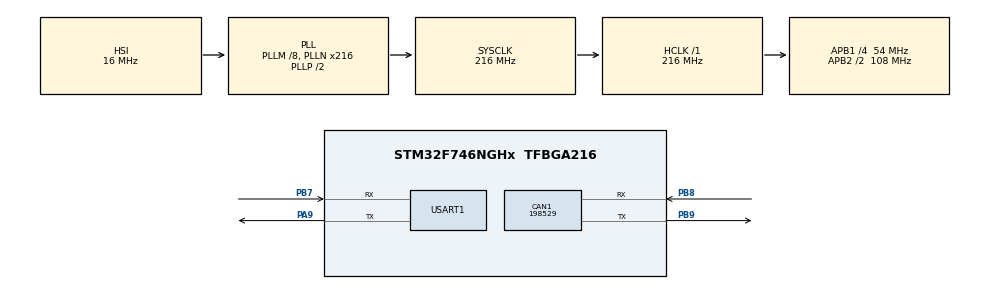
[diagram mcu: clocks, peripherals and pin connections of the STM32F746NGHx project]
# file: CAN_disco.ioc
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CAN1.BS1=CAN_BS1_8TQ
CAN1.BS2=CAN_BS2_8TQ
CAN1.CalculateBaudRate=198529
CAN1.CalculateTimeBit=5037
CAN1.CalculateTimeQuantum=296.2962962962963
CAN1.NART=ENABLE
CAN1.SJW=CAN_SJW_4TQ
Mcu.Family=STM32F7
Mcu.Name=STM32F746NGHx
Mcu.Package=TFBGA216
NVIC.PriorityGroup=NVIC_PRIORITYGROUP_4
PA9.Mode=Asynchronous
PA9.Signal=USART1_TX
PB7.Mode=Asynchronous
PB7.Signal=USART1_RX
PB8.Mode=CAN_Activate
PB8.Signal=CAN1_RX
PB9.Mode=CAN_Activate
PB9.Signal=CAN1_TX
ProjectManager.HeapSize=0x200
ProjectManager.StackSize=0x400
ProjectManager.TargetToolchain=STM32CubeIDE
RCC.AHBFreq_Value=216000000
RCC.APB1CLKDivider=RCC_HCLK_DIV4
RCC.APB1Freq_Value=54000000
RCC.APB1TimFreq_Value=108000000
RCC.APB2CLKDivider=RCC_HCLK_DIV2
RCC.APB2Freq_Value=108000000
RCC.APB2TimFreq_Value=216000000
RCC.CortexFreq_Value=216000000
RCC.HCLKFreq_Value=216000000
RCC.HSE_VALUE=25000000
RCC.HSI_VALUE=16000000
RCC.LSE_VALUE=32768
RCC.PLL48CLockSelection=RCC_CLK48SOURCE_PLLSAIP
RCC.PLLI2SN=100
RCC.PLLM=8
RCC.PLLN=216
RCC.PLLQ=9
RCC.PLLSAIN=384
RCC.PLLSAIP=RCC_PLLSAIP_DIV8
RCC.PLLSAIR=5
RCC.PLLSAIRDiv=RCC_PLLSAIDIVR_8
RCC.SDMMCClockSelection=RCC_SDMMC1CLKSOURCE_CLK48
RCC.SYSCLKFreq_VALUE=216000000
RCC.SYSCLKSource=RCC_SYSCLKSOURCE_PLLCLK
RCC.USBFreq_Value=96000000
RCC.VCOOutputFreq_Value=432000000
USART1.VirtualMode-Asynchronous=VM_ASYNC
board=STM32F746G-DISCO

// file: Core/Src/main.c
/* USER CODE BEGIN Header */
/**
  ******************************************************************************
  * @file           : main.c
  * @brief          : Main program body
  ******************************************************************************
  * @attention
  *
  * Copyright (c) 2024 STMicroelectronics.
  * All rights reserved.
  *
  * This software is licensed under terms that can be found in the LICENSE file
  * in the root directory of this software component.
  * If no LICENSE file comes with this software, it is provided AS-IS.
  *
  ******************************************************************************
  */
/* USER CODE END Header */
#include "main.h"

/* USER CODE BEGIN Includes */
#include "DELTA_variador.h"
/* USER CODE END Includes */

/* USER CODE BEGIN PTD */
variador Motor;
/* USER CODE END PTD */

CAN_HandleTypeDef hcan1;

UART_HandleTypeDef huart1;

void SystemClock_Config(void);
static void MX_GPIO_Init(void);
static void MX_CAN1_Init(void);
static void MX_USART1_UART_Init(void);

int main(void)
{

  /* MCU Configuration--------------------------------------------------------*/

  /* Reset of all peripherals, Initializes the Flash interface and the Systick. */
  HAL_Init();

  /* Configure the system clock */
  SystemClock_Config();

  /* Initialize all configured peripherals */
  MX_GPIO_Init();
  MX_CAN1_Init();
  MX_USART1_UART_Init();

  /* Infinite loop */
  while (1)
  {

  }
}

void SystemClock_Config(void)
{
  RCC_OscInitTypeDef RCC_OscInitStruct = {0};
  RCC_ClkInitTypeDef RCC_ClkInitStruct = {0};

  /** Configure the main internal regulator output voltage
  */
  __HAL_RCC_PWR_CLK_ENABLE();
  __HAL_PWR_VOLTAGESCALING_CONFIG(PWR_REGULATOR_VOLTAGE_SCALE1);

  /** Initializes the RCC Oscillators according to the specified parameters
  * in the RCC_OscInitTypeDef structure.
  */
  RCC_OscInitStruct.OscillatorType = RCC_OSCILLATORTYPE_HSI;
  RCC_OscInitStruct.HSIState = RCC_HSI_ON;
  RCC_OscInitStruct.HSICalibrationValue = RCC_HSICALIBRATION_DEFAULT;
  RCC_OscInitStruct.PLL.PLLState = RCC_PLL_ON;
  RCC_OscInitStruct.PLL.PLLSource = RCC_PLLSOURCE_HSI;
  RCC_OscInitStruct.PLL.PLLM = 8;
  RCC_OscInitStruct.PLL.PLLN = 216;
  RCC_OscInitStruct.PLL.PLLP = RCC_PLLP_DIV2;
  RCC_OscInitStruct.PLL.PLLQ = 9;
  if (HAL_RCC_OscConfig(&RCC_OscInitStruct) != HAL_OK)
  {
    Error_Handler();
  }

  /** Activate the Over-Drive mode
  */
  if (HAL_PWREx_EnableOverDrive() != HAL_OK)
  {
    Error_Handler();
  }

  /** Initializes the CPU, AHB and APB buses clocks
  */
  RCC_ClkInitStruct.ClockType = RCC_CLOCKTYPE_HCLK|RCC_CLOCKTYPE_SYSCLK
                              |RCC_CLOCKTYPE_PCLK1|RCC_CLOCKTYPE_PCLK2;
  RCC_ClkInitStruct.SYSCLKSource = RCC_SYSCLKSOURCE_PLLCLK;
  RCC_ClkInitStruct.AHBCLKDivider = RCC_SYSCLK_DIV1;
  RCC_ClkInitStruct.APB1CLKDivider = RCC_HCLK_DIV4;
  RCC_ClkInitStruct.APB2CLKDivider = RCC_HCLK_DIV2;

  if (HAL_RCC_ClockConfig(&RCC_ClkInitStruct, FLASH_LATENCY_7) != HAL_OK)
  {
    Error_Handler();
  }
}

static void MX_CAN1_Init(void)
{

  hcan1.Instance = CAN1;
  hcan1.Init.Prescaler = 16;
  hcan1.Init.Mode = CAN_MODE_NORMAL;
  hcan1.Init.SyncJumpWidth = CAN_SJW_4TQ;
  hcan1.Init.TimeSeg1 = CAN_BS1_8TQ;
  hcan1.Init.TimeSeg2 = CAN_BS2_8TQ;
  hcan1.Init.TimeTriggeredMode = DISABLE;
  hcan1.Init.AutoBusOff = DISABLE;
  hcan1.Init.AutoWakeUp = DISABLE;
  hcan1.Init.AutoRetransmission = ENABLE;
  hcan1.Init.ReceiveFifoLocked = DISABLE;
  hcan1.Init.TransmitFifoPriority = DISABLE;
  if (HAL_CAN_Init(&hcan1) != HAL_OK)
  {
    Error_Handler();
  }

}

static void MX_USART1_UART_Init(void)
{

  huart1.Instance = USART1;
  huart1.Init.BaudRate = 115200;
  huart1.Init.WordLength = UART_WORDLENGTH_8B;
  huart1.Init.StopBits = UART_STOPBITS_1;
  huart1.Init.Parity = UART_PARITY_NONE;
  huart1.Init.Mode = UART_MODE_TX_RX;
  huart1.Init.HwFlowCtl = UART_HWCONTROL_NONE;
  huart1.Init.OverSampling = UART_OVERSAMPLING_16;
  huart1.Init.OneBitSampling = UART_ONE_BIT_SAMPLE_DISABLE;
  huart1.AdvancedInit.AdvFeatureInit = UART_ADVFEATURE_NO_INIT;
  if (HAL_UART_Init(&huart1) != HAL_OK)
  {
    Error_Handler();
  }

}

static void MX_GPIO_Init(void)
{

  /* GPIO Ports Clock Enable */
  __HAL_RCC_GPIOB_CLK_ENABLE();
  __HAL_RCC_GPIOA_CLK_ENABLE();

}

void Error_Handler(void)
{
  __disable_irq();
  while (1)
  {
  }
}
